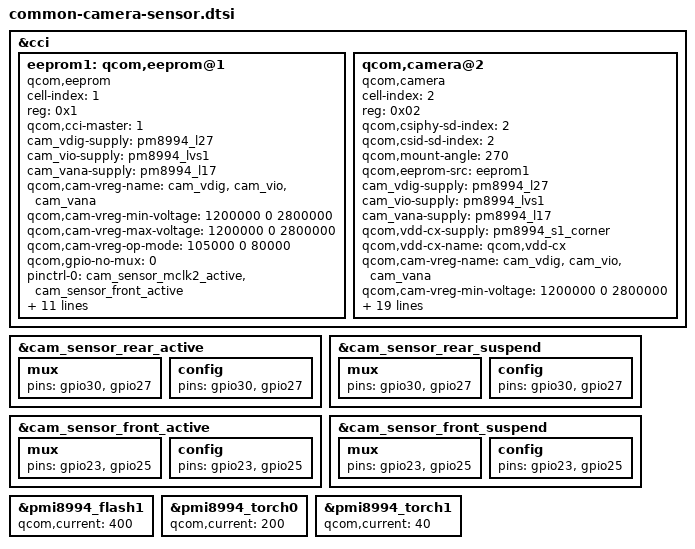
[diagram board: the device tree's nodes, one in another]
&cci {
	/delete-node/ qcom,camera@1;
	/delete-node/ qcom,eeprom@1;
	/delete-node/ qcom,camera@2;
	
	eeprom1: qcom,eeprom@1 {
		cell-index = <1>;
		reg = <0x1>;
		compatible = "qcom,eeprom";
		qcom,cci-master = <1>;
		cam_vdig-supply = <&pm8994_l27>;
		cam_vio-supply = <&pm8994_lvs1>;
		cam_vana-supply = <&pm8994_l17>;
		qcom,cam-vreg-name = "cam_vdig", "cam_vio", "cam_vana";
		qcom,cam-vreg-min-voltage = <1200000 0 2800000>;
		qcom,cam-vreg-max-voltage = <1200000 0 2800000>;
		qcom,cam-vreg-op-mode = <105000 0 80000>;
		qcom,gpio-no-mux = <0>;
		pinctrl-names = "cam_default", "cam_suspend";
		pinctrl-0 = <&cam_sensor_mclk2_active &cam_sensor_front_active>;
		pinctrl-1 = <&cam_sensor_mclk2_suspend &cam_sensor_front_suspend>;
		gpios = <&tlmm 15 0>,
			<&tlmm 23 0>,
			<&tlmm 25 0>;
		qcom,gpio-reset = <1>;
		qcom,gpio-standby = <2>;
		qcom,gpio-req-tbl-num = <0 1 2>;
		qcom,gpio-req-tbl-flags = <1 0 0>;
		qcom,gpio-req-tbl-label = "CAMIF_MCLK2",
					  "CAM_RESET2",
					  "CAM_STANDBY2";
		clocks = <&clock_mmss clk_mclk2_clk_src>,
			<&clock_mmss clk_camss_mclk2_clk>;
		clock-names = "cam_src_clk", "cam_clk";
	};
	
	qcom,camera@2 {
		cell-index = <2>;
		compatible = "qcom,camera";
		reg = <0x02>;
		qcom,csiphy-sd-index = <2>;
		qcom,csid-sd-index = <2>;
		qcom,mount-angle = <270>;
		qcom,eeprom-src = <&eeprom1>;
		cam_vdig-supply = <&pm8994_l27>;
		cam_vio-supply = <&pm8994_lvs1>;
		cam_vana-supply = <&pm8994_l17>;
		qcom,vdd-cx-supply = <&pm8994_s1_corner>;
		qcom,vdd-cx-name = "qcom,vdd-cx";
		qcom,cam-vreg-name = "cam_vdig", "cam_vio", "cam_vana";
		qcom,cam-vreg-min-voltage = <1200000 0 2800000>;
		qcom,cam-vreg-max-voltage = <1200000 0 2800000>;
		qcom,cam-vreg-op-mode = <105000 0 80000>;
		qcom,gpio-no-mux = <0>;
		pinctrl-names = "cam_default", "cam_suspend";
		pinctrl-0 = <&cam_sensor_mclk2_active &cam_sensor_front_active>;
		pinctrl-1 = <&cam_sensor_mclk2_suspend &cam_sensor_front_suspend>;
		gpios = <&tlmm 15 0>,
			<&tlmm 23 0>,
			<&tlmm 25 0>;
		qcom,gpio-reset = <1>;
		qcom,gpio-standby = <2>;
		qcom,gpio-req-tbl-num = <0 1 2>;
		qcom,gpio-req-tbl-flags = <1 0 0>;
		qcom,gpio-req-tbl-label = "CAMIF_MCLK2",
					  "CAM_RESET2",
					  "CAM_STANDBY2";
		qcom,sensor-position = <1>;
		qcom,sensor-mode = <0>;
		qcom,cci-master = <1>;
		status = "ok";
		clocks = <&clock_mmss clk_mclk2_clk_src>,
			<&clock_mmss clk_camss_mclk2_clk>;
		clock-names = "cam_src_clk", "cam_clk";
	};
};

&cam_sensor_rear_active {
	mux {
		pins = "gpio30", "gpio27";
	};
	config {
		pins = "gpio30", "gpio27";
	};
};

&cam_sensor_rear_suspend {
	mux {
		pins = "gpio30", "gpio27";
	};
	config {
		pins = "gpio30", "gpio27";
	};
};

&cam_sensor_front_active {
	mux {
		pins = "gpio23","gpio25";
	};
	config {
		pins = "gpio23","gpio25";
	};
};

&cam_sensor_front_suspend {
	mux {
		pins = "gpio23","gpio25";
	};
	config {
		pins = "gpio23","gpio25";
	};
};

&pmi8994_flash1 {
	qcom,current = <400>;
};

&pmi8994_torch0 {
	qcom,current = <200>;
};

&pmi8994_torch1 {
	qcom,current = <40>;
};
